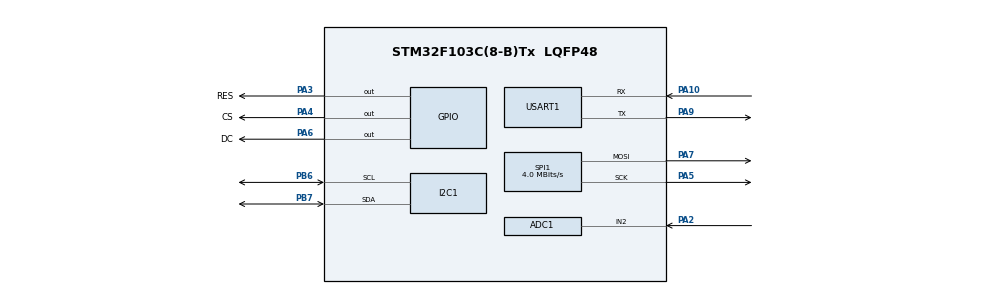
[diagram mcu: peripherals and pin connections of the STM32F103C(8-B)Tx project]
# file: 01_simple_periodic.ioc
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ADC1.Channel-0\#ChannelRegularConversion=ADC_CHANNEL_2
ADC1.NbrOfConversionFlag=1
ADC1.Rank-0\#ChannelRegularConversion=1
ADC1.SamplingTime-0\#ChannelRegularConversion=ADC_SAMPLETIME_1CYCLE_5
ADC1.master=1
Mcu.Family=STM32F1
Mcu.Name=STM32F103C(8-B)Tx
Mcu.Package=LQFP48
NVIC.PriorityGroup=NVIC_PRIORITYGROUP_4
NVIC.TIM1_UP_IRQn=true\:0\:0\:false\:false\:true\:true\:true
PA10.Mode=Asynchronous
PA10.Signal=USART1_RX
PA2.Signal=ADCx_IN2
PA3.GPIO_Label=RES
PA3.Signal=GPIO_Output
PA4.GPIO_Label=CS
PA4.Signal=GPIO_Output
PA5.Mode=TX_Only_Simplex_Unidirect_Master
PA5.Signal=SPI1_SCK
PA6.GPIO_Label=DC
PA6.Signal=GPIO_Output
PA7.Mode=TX_Only_Simplex_Unidirect_Master
PA7.Signal=SPI1_MOSI
PA9.Mode=Asynchronous
PA9.Signal=USART1_TX
PB6.Mode=I2C
PB6.Signal=I2C1_SCL
PB7.Mode=I2C
PB7.Signal=I2C1_SDA
ProjectManager.HeapSize=0x200
ProjectManager.StackSize=0x400
ProjectManager.TargetToolchain=STM32CubeIDE
RCC.APB1Freq_Value=8000000
RCC.APB2Freq_Value=8000000
SH.ADCx_IN2.0=ADC1_IN2,IN2
SPI1.CalculateBaudRate=4.0 MBits/s
SPI1.Direction=SPI_DIRECTION_2LINES
SPI1.Mode=SPI_MODE_MASTER
SPI1.VirtualType=VM_MASTER
TIM1.Period=4999
TIM1.Prescaler=7999
USART1.VirtualMode=VM_ASYNC
VP_SYS_VS_ND.Mode=No_Debug
VP_TIM1_VS_ClockSourceINT.Mode=Internal
board=custom

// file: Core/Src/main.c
#include "main.h"

#include <stdint.h>
#include <stdarg.h>
#include <stdio.h>
#include <string.h>
#include "oled.h"
#include "aht10.h"

/* USER CODE BEGIN Includes */
sensor_typedef m_sensor;
volatile uint8_t flag = 0;
volatile uint32_t period = 5000;

#define UART_RX_BUFFER_SIZE 128
static uint8_t uart_rx_buffer[UART_RX_BUFFER_SIZE];
static uint8_t uart_rx_data;
static uint16_t uart_rx_index = 0;

/* USER CODE END Includes */

ADC_HandleTypeDef hadc1;

I2C_HandleTypeDef hi2c1;

SPI_HandleTypeDef hspi1;

TIM_HandleTypeDef htim1;

UART_HandleTypeDef huart1;

void SystemClock_Config(void);
static void MX_GPIO_Init(void);
static void MX_I2C1_Init(void);
static void MX_TIM1_Init(void);
static void MX_USART1_UART_Init(void);
static void MX_SPI1_Init(void);
static void MX_ADC1_Init(void);

void serial_print(const char *format,...)
{
	char buff[128];
	va_list args;
	va_start(args, format);
	int len = vsnprintf(buff, sizeof(buff), format, args);
	va_end(args);

	if (len > 0) {
	    if (len > sizeof(buff)) len = sizeof(buff);
	    HAL_UART_Transmit(&huart1, (uint8_t*)buff, len, 500);
	}
}

void uart_rx_IT() {
    uart_rx_index = 0;
    memset(uart_rx_buffer, 0, UART_RX_BUFFER_SIZE);
    HAL_UART_Receive_IT(&huart1, &uart_rx_data, 1);
}

void TIM1_SetPeriod(uint32_t period_ms)
{
    uint32_t psc = 7999;
    uint32_t arr = period_ms - 1;

    HAL_TIM_Base_Stop_IT(&htim1);

    __HAL_TIM_SET_PRESCALER(&htim1, psc);
    __HAL_TIM_SET_AUTORELOAD(&htim1, arr);
    __HAL_TIM_SET_COUNTER(&htim1, 0);

    HAL_TIM_Base_Start_IT(&htim1);
}

void HAL_UART_RxCpltCallback(UART_HandleTypeDef *huart) {
    if (huart->Instance == USART1) {
        if (uart_rx_index < UART_RX_BUFFER_SIZE - 1) {
            uart_rx_buffer[uart_rx_index++] = uart_rx_data;

            if (uart_rx_data == '.') {
                uart_rx_buffer[uart_rx_index] = '\0';
                uart_rx_process((char *)uart_rx_buffer);
                uart_rx_index = 0;
                memset(uart_rx_buffer, 0, UART_RX_BUFFER_SIZE);
            }
        } else {
            uart_rx_index = 0;
        }

        HAL_UART_Receive_IT(&huart1, &uart_rx_data, 1);
    }
}

void uart_rx_process(char *data)
{
	uint32_t value;

	if (sscanf(data, "change_period: %lu.", &value) == 1)
		    	{
		    	    TIM1_SetPeriod(value);
		    	    period = value;
		    	    serial_print("period = %lu ms\r\n", value);
		    	}

	else
	{
		serial_print("Invalid command format\r\n");
	}
}
void HAL_TIM_PeriodElapsedCallback(TIM_HandleTypeDef *htim)
{
    if (htim->Instance == TIM1)
    {
    	serial_print("%lu ms interrupt \r\n", period);
    	flag  = 1;
    }
}

void task_aht10_read()
{
	serial_print("handle task aht\r\n");
	aht10_get_data(&m_sensor);
}

void task_soil_read()
{
	serial_print("handle task soil\r\n");
	moisture_get(4500, 1500, &m_sensor);
}

void task_oled_display()
{
	serial_print("handle task oled\r\n");
	char oled_buf[32];

		  sprintf(oled_buf, "TEMP: %d.%d C", m_sensor.temp/100, m_sensor.temp %100);
		  oled_msg(3, 20, oled_buf);
		  sprintf(oled_buf, "HUMID: %d.%d %%", m_sensor.humidity/100, m_sensor.humidity %100);
		  oled_msg(5, 20, oled_buf);
		  sprintf(oled_buf, "MOISTURE: %d.%d %%", m_sensor.soil_moisture/100, m_sensor.soil_moisture %100);
		  oled_msg(7, 20, oled_buf);

}

void task_uart_send()
{
	serial_print("handle task uart\r\n");
	serial_print("TEMP: %d.%d | HUMID: %d.%d | MOISTURE: %d.%d|\r\n",
			m_sensor.temp/100, m_sensor.temp %100,
			m_sensor.humidity/100, m_sensor.humidity %100,
			m_sensor.soil_moisture/100, m_sensor.soil_moisture %100);
}

void task_execute_periodic()
{
	task_aht10_read();
	task_soil_read();
	task_oled_display();
	task_uart_send();
}

int main(void)
{

  /* MCU Configuration--------------------------------------------------------*/

  /* Reset of all peripherals, Initializes the Flash interface and the Systick. */
  HAL_Init();

  /* Configure the system clock */
  SystemClock_Config();

  /* Initialize all configured peripherals */
  MX_GPIO_Init();
  MX_I2C1_Init();
  MX_TIM1_Init();
  MX_USART1_UART_Init();
  MX_SPI1_Init();
  MX_ADC1_Init();
  /* USER CODE BEGIN 2 */
  HAL_TIM_Base_Start_IT(&htim1);
  oled_init();
  oled_clear();

  uart_rx_IT();
  /* USER CODE END 2 */

  /* Infinite loop */
  while (1)
  {
	  if (flag)
	  	  	    {
	  	  	        flag = 0;
	  	  	        task_execute_periodic();
	  	  	    }

  }
}

void SystemClock_Config(void)
{
  RCC_OscInitTypeDef RCC_OscInitStruct = {0};
  RCC_ClkInitTypeDef RCC_ClkInitStruct = {0};
  RCC_PeriphCLKInitTypeDef PeriphClkInit = {0};

  /** Initializes the RCC Oscillators according to the specified parameters
  * in the RCC_OscInitTypeDef structure.
  */
  RCC_OscInitStruct.OscillatorType = RCC_OSCILLATORTYPE_HSI;
  RCC_OscInitStruct.HSIState = RCC_HSI_ON;
  RCC_OscInitStruct.HSICalibrationValue = RCC_HSICALIBRATION_DEFAULT;
  RCC_OscInitStruct.PLL.PLLState = RCC_PLL_NONE;
  if (HAL_RCC_OscConfig(&RCC_OscInitStruct) != HAL_OK)
  {
    Error_Handler();
  }
  /** Initializes the CPU, AHB and APB buses clocks
  */
  RCC_ClkInitStruct.ClockType = RCC_CLOCKTYPE_HCLK|RCC_CLOCKTYPE_SYSCLK
                              |RCC_CLOCKTYPE_PCLK1|RCC_CLOCKTYPE_PCLK2;
  RCC_ClkInitStruct.SYSCLKSource = RCC_SYSCLKSOURCE_HSI;
  RCC_ClkInitStruct.AHBCLKDivider = RCC_SYSCLK_DIV1;
  RCC_ClkInitStruct.APB1CLKDivider = RCC_HCLK_DIV1;
  RCC_ClkInitStruct.APB2CLKDivider = RCC_HCLK_DIV1;

  if (HAL_RCC_ClockConfig(&RCC_ClkInitStruct, FLASH_LATENCY_0) != HAL_OK)
  {
    Error_Handler();
  }
  PeriphClkInit.PeriphClockSelection = RCC_PERIPHCLK_ADC;
  PeriphClkInit.AdcClockSelection = RCC_ADCPCLK2_DIV2;
  if (HAL_RCCEx_PeriphCLKConfig(&PeriphClkInit) != HAL_OK)
  {
    Error_Handler();
  }
}

static void MX_ADC1_Init(void)
{

  ADC_ChannelConfTypeDef sConfig = {0};

  /** Common config
  */
  hadc1.Instance = ADC1;
  hadc1.Init.ScanConvMode = ADC_SCAN_DISABLE;
  hadc1.Init.ContinuousConvMode = DISABLE;
  hadc1.Init.DiscontinuousConvMode = DISABLE;
  hadc1.Init.ExternalTrigConv = ADC_SOFTWARE_START;
  hadc1.Init.DataAlign = ADC_DATAALIGN_RIGHT;
  hadc1.Init.NbrOfConversion = 1;
  if (HAL_ADC_Init(&hadc1) != HAL_OK)
  {
    Error_Handler();
  }
  /** Configure Regular Channel
  */
  sConfig.Channel = ADC_CHANNEL_2;
  sConfig.Rank = ADC_REGULAR_RANK_1;
  sConfig.SamplingTime = ADC_SAMPLETIME_1CYCLE_5;
  if (HAL_ADC_ConfigChannel(&hadc1, &sConfig) != HAL_OK)
  {
    Error_Handler();
  }

}

static void MX_I2C1_Init(void)
{

  hi2c1.Instance = I2C1;
  hi2c1.Init.ClockSpeed = 100000;
  hi2c1.Init.DutyCycle = I2C_DUTYCYCLE_2;
  hi2c1.Init.OwnAddress1 = 0;
  hi2c1.Init.AddressingMode = I2C_ADDRESSINGMODE_7BIT;
  hi2c1.Init.DualAddressMode = I2C_DUALADDRESS_DISABLE;
  hi2c1.Init.OwnAddress2 = 0;
  hi2c1.Init.GeneralCallMode = I2C_GENERALCALL_DISABLE;
  hi2c1.Init.NoStretchMode = I2C_NOSTRETCH_DISABLE;
  if (HAL_I2C_Init(&hi2c1) != HAL_OK)
  {
    Error_Handler();
  }

}

static void MX_SPI1_Init(void)
{

  /* SPI1 parameter configuration*/
  hspi1.Instance = SPI1;
  hspi1.Init.Mode = SPI_MODE_MASTER;
  hspi1.Init.Direction = SPI_DIRECTION_2LINES;
  hspi1.Init.DataSize = SPI_DATASIZE_8BIT;
  hspi1.Init.CLKPolarity = SPI_POLARITY_LOW;
  hspi1.Init.CLKPhase = SPI_PHASE_1EDGE;
  hspi1.Init.NSS = SPI_NSS_SOFT;
  hspi1.Init.BaudRatePrescaler = SPI_BAUDRATEPRESCALER_2;
  hspi1.Init.FirstBit = SPI_FIRSTBIT_MSB;
  hspi1.Init.TIMode = SPI_TIMODE_DISABLE;
  hspi1.Init.CRCCalculation = SPI_CRCCALCULATION_DISABLE;
  hspi1.Init.CRCPolynomial = 10;
  if (HAL_SPI_Init(&hspi1) != HAL_OK)
  {
    Error_Handler();
  }

}

static void MX_TIM1_Init(void)
{

  TIM_ClockConfigTypeDef sClockSourceConfig = {0};
  TIM_MasterConfigTypeDef sMasterConfig = {0};

  htim1.Instance = TIM1;
  htim1.Init.Prescaler = 7999;
  htim1.Init.CounterMode = TIM_COUNTERMODE_UP;
  htim1.Init.Period = 4999;
  htim1.Init.ClockDivision = TIM_CLOCKDIVISION_DIV1;
  htim1.Init.RepetitionCounter = 0;
  htim1.Init.AutoReloadPreload = TIM_AUTORELOAD_PRELOAD_DISABLE;
  if (HAL_TIM_Base_Init(&htim1) != HAL_OK)
  {
    Error_Handler();
  }
  sClockSourceConfig.ClockSource = TIM_CLOCKSOURCE_INTERNAL;
  if (HAL_TIM_ConfigClockSource(&htim1, &sClockSourceConfig) != HAL_OK)
  {
    Error_Handler();
  }
  sMasterConfig.MasterOutputTrigger = TIM_TRGO_RESET;
  sMasterConfig.MasterSlaveMode = TIM_MASTERSLAVEMODE_DISABLE;
  if (HAL_TIMEx_MasterConfigSynchronization(&htim1, &sMasterConfig) != HAL_OK)
  {
    Error_Handler();
  }

}

static void MX_USART1_UART_Init(void)
{

  huart1.Instance = USART1;
  huart1.Init.BaudRate = 115200;
  huart1.Init.WordLength = UART_WORDLENGTH_8B;
  huart1.Init.StopBits = UART_STOPBITS_1;
  huart1.Init.Parity = UART_PARITY_NONE;
  huart1.Init.Mode = UART_MODE_TX_RX;
  huart1.Init.HwFlowCtl = UART_HWCONTROL_NONE;
  huart1.Init.OverSampling = UART_OVERSAMPLING_16;
  if (HAL_UART_Init(&huart1) != HAL_OK)
  {
    Error_Handler();
  }

}

static void MX_GPIO_Init(void)
{
  GPIO_InitTypeDef GPIO_InitStruct = {0};

  /* GPIO Ports Clock Enable */
  __HAL_RCC_GPIOA_CLK_ENABLE();
  __HAL_RCC_GPIOB_CLK_ENABLE();

  /*Configure GPIO pin Output Level */
  HAL_GPIO_WritePin(GPIOA, RES_Pin|CS_Pin|DC_Pin, GPIO_PIN_RESET);

  /*Configure GPIO pins : RES_Pin CS_Pin DC_Pin */
  GPIO_InitStruct.Pin = RES_Pin|CS_Pin|DC_Pin;
  GPIO_InitStruct.Mode = GPIO_MODE_OUTPUT_PP;
  GPIO_InitStruct.Pull = GPIO_NOPULL;
  GPIO_InitStruct.Speed = GPIO_SPEED_FREQ_LOW;
  HAL_GPIO_Init(GPIOA, &GPIO_InitStruct);

}

void Error_Handler(void)
{
  __disable_irq();
  while (1)
  {
  }
}
